AUTOSAR XML (schema 302)
standard types defined: Boolean, Double
package /ComponentType
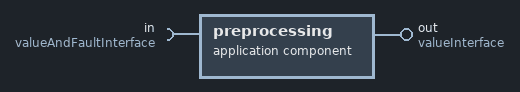
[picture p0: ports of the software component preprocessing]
  application software component type preprocessing
    provide port out: unqueued-sender-com-spec{data-element=value, can-invalidate=false}, provided-interface=valueInterface
    require port in: required-com-specs=[{data-element=faults, resync-time=0}, {data-element=values, resync-time=0}], required-interface=valueAndFaultInterface
  internal behavior preprocessing_InternalBehavior: component=preprocessing
    port-api-options:
      enable-take-address=false, indirect-api=false, port=in
      enable-take-address=false, indirect-api=false, port=out
  swc implementation preprocessing_Implementation: behavior=preprocessing_InternalBehavior
    code-descriptors:
      code Code: type=SRC
package /DataType
  record type Boolean_pair
    record element primary: type=Boolean
    record element secondary: type=Boolean
  record type Double_pair
    record element primary: type=Double
    record element secondary: type=Double
package /PortInterface
  sender receiver interface valueAndFaultInterface
    data faults: type=Boolean_pair
    data values: type=Double_pair
  sender receiver interface valueInterface
    data value: type=Double
